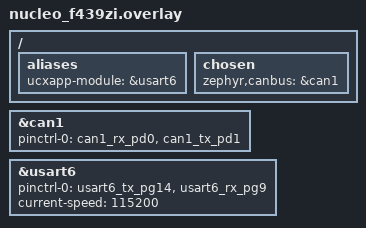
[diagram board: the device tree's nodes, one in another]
/* NORA-W36 on the Arduino header CN10 (same wiring as the FreeRTOS build):
 * module TX -> D0 = PG9 (USART6_RX), module RX <- D1 = PG14 (USART6_TX).
 * The shell stays on the ST-Link virtual COM port (USART3, zephyr,console). */

/ {
	aliases {
		ucxapp-module = &usart6;
	};
	chosen {
		/* can.* on CAN1, RX PD0, TX PD1 (CN9), as in the FreeRTOS build. */
		zephyr,canbus = &can1;
	};
};

&can1 {
	pinctrl-0 = <&can1_rx_pd0 &can1_tx_pd1>;
	pinctrl-names = "default";
	status = "okay";
};

&usart6 {
	pinctrl-0 = <&usart6_tx_pg14 &usart6_rx_pg9>;
	pinctrl-names = "default";
	current-speed = <115200>;
	status = "okay";
};
